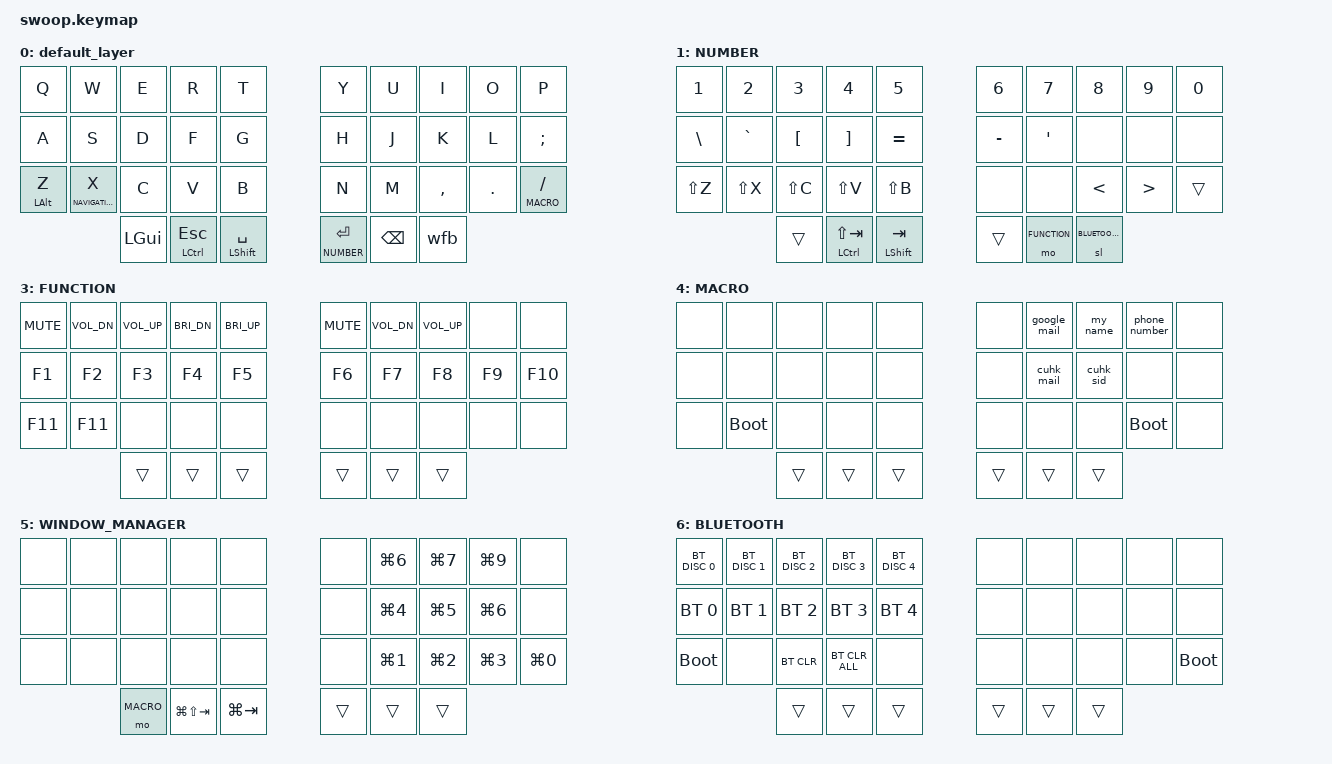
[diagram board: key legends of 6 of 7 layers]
/*
 * Copyright (c) 2020 The ZMK Contributors
 *
 * SPDX-License-Identifier: MIT
 */

#include <behaviors.dtsi>
#include <dt-bindings/zmk/keys.h>
#include <dt-bindings/zmk/bt.h>

#define NUMBER 1
#define NAVIGATION 2
#define FUNCTION 3
#define MACRO 4
#define WINDOW_MANAGER 5
#define BLUETOOTH 6
#define UPPER 7
#define LOWER 8
// #define GAME 7
// #define GAME_NUMBER 8

&lt {
    flavor = "hold-preferred";
    quick-tap-ms = <0>;
};

&sl {
    release-after-ms = <2000>;
};

/ {

    behaviors {

        rpi: require_prior_idle {
            compatible = "zmk,behavior-hold-tap";
            #binding-cells = <2>;
            flavor = "tap-preferred";
            tapping-term-ms = <200>;
            quick-tap-ms = <200>;
            require-prior-idle-ms = <125>;
            bindings = <&kp>, <&kp>;
     };

        ltrpi: layer_tap_require_prior_idle {
            compatible = "zmk,behavior-hold-tap";
            #binding-cells = <2>;
            flavor = "tap-preferred";
            tapping-term-ms = <200>;
            quick-tap-ms = <200>;
            require-prior-idle-ms = <125>;
            bindings = <&mo>, <&kp>;
     };

        wfb: window_function_bluetooth {
            compatible = "zmk,behavior-tap-dance";
            #binding-cells = <0>;
            tapping-term-ms = <200>;
            bindings = <&mo WINDOW_MANAGER>, <&sl FUNCTION>, <&sl BLUETOOTH>;
           };

    };

    macros {

        google_mail: google_mail {
            compatible = "zmk,behavior-macro";
            #binding-cells = <0>;
            wait-ms = <30>;
            tap-ms = <30>;
            bindings = <&kp S>, <&kp O>, <&kp S>, <&kp O>, <&kp K>, <&kp I>, <&kp N>, <&kp P>, <&kp U>, <&kp I>, <&kp AT>, <&kp G>, <&kp M>, <&kp A>, <&kp I>, <&kp L>, <&kp DOT>, <&kp C>, <&kp O>, <&kp M> ;
                    };

        cuhk_mail: cuhk_mail {
            compatible = "zmk,behavior-macro";
            #binding-cells = <0>;
            wait-ms = <30>;
            tap-ms = <30>;
            bindings =
            <&kp N1>, <&kp N1>, <&kp N5>, <&kp N5>, <&kp N1>, <&kp N9>, <&kp N3>, <&kp N5>, <&kp N0>, <&kp N6>, <&kp AT>, <&kp L>, <&kp I>, <&kp N>, <&kp K>, <&kp DOT>, <&kp C>, <&kp U>, <&kp H>, <&kp K>, <&kp DOT>, <&kp E>, <&kp D>, <&kp U>, <&kp DOT>, <&kp H>, <&kp K>
                ;};

        my_name: my_name {
            compatible = "zmk,behavior-macro";
            #binding-cells = <0>;
            wait-ms = <30>;
            tap-ms = <30>;
            bindings =
<&kp LS(S)>, <&kp O>, <&kp SPACE>, <&kp LS(K)>, <&kp I>, <&kp N>, <&kp SPACE>, <&kp LS(P)>, <&kp U>, <&kp I>
                ;};

        phone_number: phone_number {
            compatible = "zmk,behavior-macro";
            #binding-cells = <0>;
            wait-ms = <30>;
            tap-ms = <30>;
            bindings =
<&kp N5>, <&kp N5>, <&kp N3>, <&kp N2>, <&kp N9>, <&kp N4>, <&kp N7>, <&kp N0>
                ;};

        cuhk_sid: cuhk_sid {
            compatible = "zmk,behavior-macro";
            #binding-cells = <0>;
            wait-ms = <30>;
            tap-ms = <30>;
            bindings =
<&kp N1>, <&kp N1>, <&kp N5>, <&kp N5>, <&kp N1>, <&kp N9>, <&kp N3>, <&kp N5>, <&kp N0>, <&kp N6>
                ;};

    };

        keymap {
                compatible = "zmk,keymap";

                default_layer {
                        bindings = <
     &kp Q &kp W &kp E &kp R &kp T   &kp Y &kp U  &kp I     &kp O   &kp P
     &kp A &kp S &kp D &kp F &kp G   &kp H &kp J  &kp K     &kp L   &kp SEMI
     &rpi LALT Z &ltrpi NAVIGATION X &kp C &kp V &kp B   &kp N &kp M  &kp COMMA &kp DOT &ltrpi MACRO FSLH
                  &kp LGUI &mt LCTRL ESC &mt LSHIFT SPACE   &lt NUMBER RET &kp BSPC &wfb
                        >;
                };

                NUMBER {
                        bindings = <
   &kp N1 &kp N2 &kp N3 &kp N4 &kp N5   &kp N6 &kp N7  &kp N8     &kp N9   &kp N0
   &kp BSLH &kp GRAVE &kp LBKT &kp RBKT &kp EQUAL   &kp MINUS &kp SQT  &none     &none  &none
   &kp LS(Z) &kp LS(X) &kp LS(C) &kp LS(V) &kp LS(B)   &none &none  &kp LT &kp GT &trans
                  &trans &mt LCTRL LS(TAB) &mt LSHIFT TAB   &trans &mo FUNCTION &sl BLUETOOTH
                        >;
                };

   //              EXTRA {
   //                      bindings = <
   // &kp LA(TAB)   &kp LA(Q) &kp LA(W) &kp LA(E) &kp LA(R) &kp LA(T)   &kp LA(Y) &kp RBKT  &kp LBKT     &kp BSLH   &kp LA(P)    &kp LA(SQT)
   // &trans &kp LA(A) &kp LA(S) &kp LA(D) &kp LA(F) &kp LA(G)   &kp LA(H) &kp RBRC  &kp LBRC     &kp LA(L)   &kp LA(SEMI) &kp LA(MINUS)
   // &trans  &kp LA(Z) &kp LA(X) &kp LA(C) &kp LA(V) &kp LA(B)   &kp LA(N) &kp RPAR  &kp LPAR &kp LA(DOT) &kp LA(FSLH) &kp LA(DEL)
   //                &kp PSCRN &kp PSCRN &kp LA(SPACE)   &kp LA(RET) &kp LA(BSPC) &kp LA(DOT)
   //                      >;
   //              };

                NAVIGATION {
                        bindings = <
   &kp LC(Q) &kp UP &kp LC(E) &kp LC(R) &kp LC(T)   &kp LS(LEFT) &kp LS(DOWN)  &kp LS(UP)     &kp LS(RIGHT)   &kp CAPS
   &kp LEFT &kp DOWN &kp RIGHT &kp LC(F) &kp LC(G)   &kp LEFT &kp DOWN  &kp UP     &kp RIGHT   &kp LC(MINUS) &trans
   &kp LC(Z) &kp LC(X) &bootloader &kp LC(V) &kp LC(B)   &kp HOME &kp PG_DN  &kp PG_UP &kp END &trans &trans
                  &trans &trans &trans   &kp RSHIFT &kp DEL &trans
                        >;
                };

                FUNCTION {
                        bindings = <
   &kp C_MUTE &kp C_VOL_DN &kp C_VOL_UP &kp C_BRI_DN &kp C_BRI_UP   &kp C_MUTE &kp C_VOL_DN  &kp C_VOL_UP     &none   &none
   &kp F1 &kp F2 &kp F3 &kp F4 &kp F5   &kp F6 &kp F7  &kp F8     &kp F9   &kp F10
   &kp F11 &kp F11 &none &none &none   &none &none  &none &none &none
                  &trans &trans &trans   &trans &trans &trans
                        >;
                };


                MACRO {
                        bindings = <
   &none &none &none &none &none   &none &google_mail  &my_name &phone_number &none
   &none &none &none &none &none   &none &cuhk_mail  &cuhk_sid &none &none
   &none &bootloader &none &none &none   &none &none  &none &bootloader &none
                  &trans &trans &trans   &trans &trans &trans
                        >;
                };

                WINDOW_MANAGER {
                        bindings = <
   &none &none &none &none &none   &none &kp LG(N6)  &kp LG(N7) &kp LG(N9) &none
   &none &none &none &none &none   &none &kp LG(N4)  &kp LG(N5) &kp LG(N6) &none
   &none &none &none &none &none   &none &kp LG(N1)  &kp LG(N2) &kp LG(N3) &kp LG(N0)
                  &mo MACRO &kp LG(LS(TAB)) &kp LG(TAB)   &trans &trans &trans
                        >;
                };

                BLUETOOTH {
                        bindings = <
   &bt BT_DISC 0 &bt BT_DISC 1 &bt BT_DISC 2 &bt BT_DISC 3 &bt BT_DISC 4   &none &none  &none &none &none
   &bt BT_SEL 0 &bt BT_SEL 1 &bt BT_SEL 2 &bt BT_SEL 3 &bt BT_SEL 4   &none &none  &none &none &none
   &bootloader &none &bt BT_CLR &bt BT_CLR_ALL &none   &none &none  &none &none &bootloader
            &trans &trans &trans   &trans &trans &trans
                      >;
              };


   //        LOWER {
   //                bindings = <
   // &none &none &none &none &none   &none &none  &none &none &none
   // &none &none &none &none &none   &kp LG(LEFT) &kp LG(DOWN)  &kp LG(UP) &kp LG(RIGHT) &none
   // &none &none &none &none &none   &none &none  &none &none &none
   //          &trans &trans &trans   &trans &trans &trans
   //                >;
   //        };
   //
   //        UPPER {
   //                bindings = <
   // &none &none &none &none &none   &none &none  &none &kp LG(LS(LC(LA(N1)))) &kp LG(LS(LC(LA(N2)))) &kp LG(N7)
   // &none &none &none &none &none   &none &none  &none &kp LG(LS(LC(LA(N3)))) &kp LG(LS(LC(LA(N4)))) &kp LG(N8)
   // &none &none &none &none &none   &none &none  &none &none &none &kp LG(N9)
   //                &trans &trans &trans   &trans &trans &trans
   //                      >;
   //              };

   //              GAME {
   //                      bindings = <
   // &tog GAME  &kp TAB    &kp Q &kp W &kp E &kp R    &kp Y &kp U  &kp I     &kp O   &kp P    &kp SQT
   // &none      &kp LCTRL  &kp A &kp S &kp D &kp F    &kp H &kp J  &kp K     &kp L   &kp SEMI &kp MINUS
   // &none      &kp LSHIFT &kp Z &kp X &kp C &kp V    &kp N &kp M  &kp COMMA &kp DOT &kp FSLH &mt LSHIFT DEL
   //                &kp LGUI &mo GAME_NUMBER &kp SPACE   &lt NUMBER RET &kp BSPC &wfb
   //                      >;
   //              };
   //
   //              GAME_NUMBER {
   //                      bindings = <
   // &tog GAME  &kp N1  &kp N2 &kp N3 &kp N4 &kp N5    &kp Y &kp U  &kp I     &kp O   &kp P    &kp SQT
   // &none      &kp N6  &kp N7 &kp N8 &kp N9 &kp N0    &kp H &kp J  &kp K     &kp L   &kp SEMI &kp MINUS
   // &none      &kp LSHIFT &kp Z &kp X &kp C &kp V    &kp N &kp M  &kp COMMA &kp DOT &kp FSLH &mt LSHIFT DEL
   //                &kp LGUI &mo GAME_NUMBER &kp SPACE   &lt NUMBER RET &kp BSPC &wfb
                        // >;
                // };

        };
};
